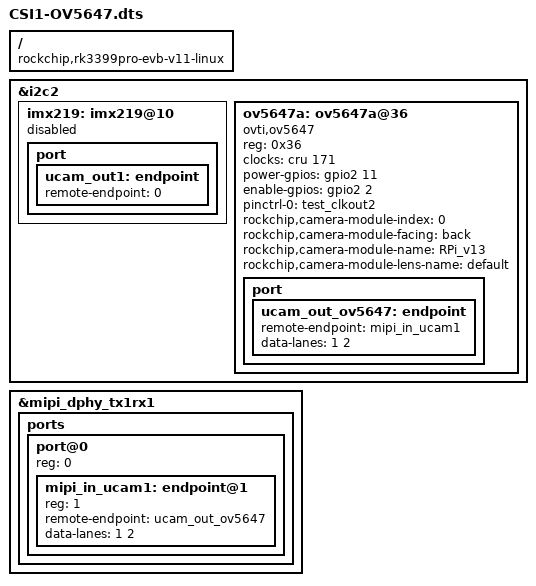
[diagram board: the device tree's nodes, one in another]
/dts-v1/;
/plugin/;
/ {
	compatible = "rockchip,rk3399pro-evb-v11-linux";

	fragment@0 {
		target = <&i2c2>;
		__overlay__ {
			status = "okay";

			imx219: imx219@10 {
				status = "disabled";
				port {
					ucam_out1: endpoint {
						remote-endpoint=<0>;
					};
				};
			};

			ov5647a: ov5647a@36 {
				compatible = "ovti,ov5647";
				status = "okay";
				reg = <0x36>;
				clocks = <&cru 171>;
				clock-names = "xvclk";

				/* conflict with csi-ctl-gpios */
				power-gpios = <&gpio2 11 0>;
				enable-gpios = <&gpio2 2 0>;
				pinctrl-names = "camera_default";
				pinctrl-0 = <&test_clkout2>;
				rockchip,camera-module-index = <0>;
				rockchip,camera-module-facing = "back";
				rockchip,camera-module-name = "RPi_v13";
				rockchip,camera-module-lens-name = "default";

				port {
					ucam_out_ov5647: endpoint {
						remote-endpoint = <&mipi_in_ucam1>;
						data-lanes = <1 2>;
					};
				};
			};
		};
	};

	fragment@1 {
		target = <&mipi_dphy_tx1rx1>;
		__overlay__ {
			status = "okay";

			ports {
				port@0 {
					reg = <0>;
					mipi_in_ucam1: endpoint@1 {
						reg = <1>;
						remote-endpoint = <&ucam_out_ov5647>;
						data-lanes = <1 2>;
					};
				};
			};
		};
	};
};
